AUTOSAR XML (schema 4-0-3)
package /ComponentTypes
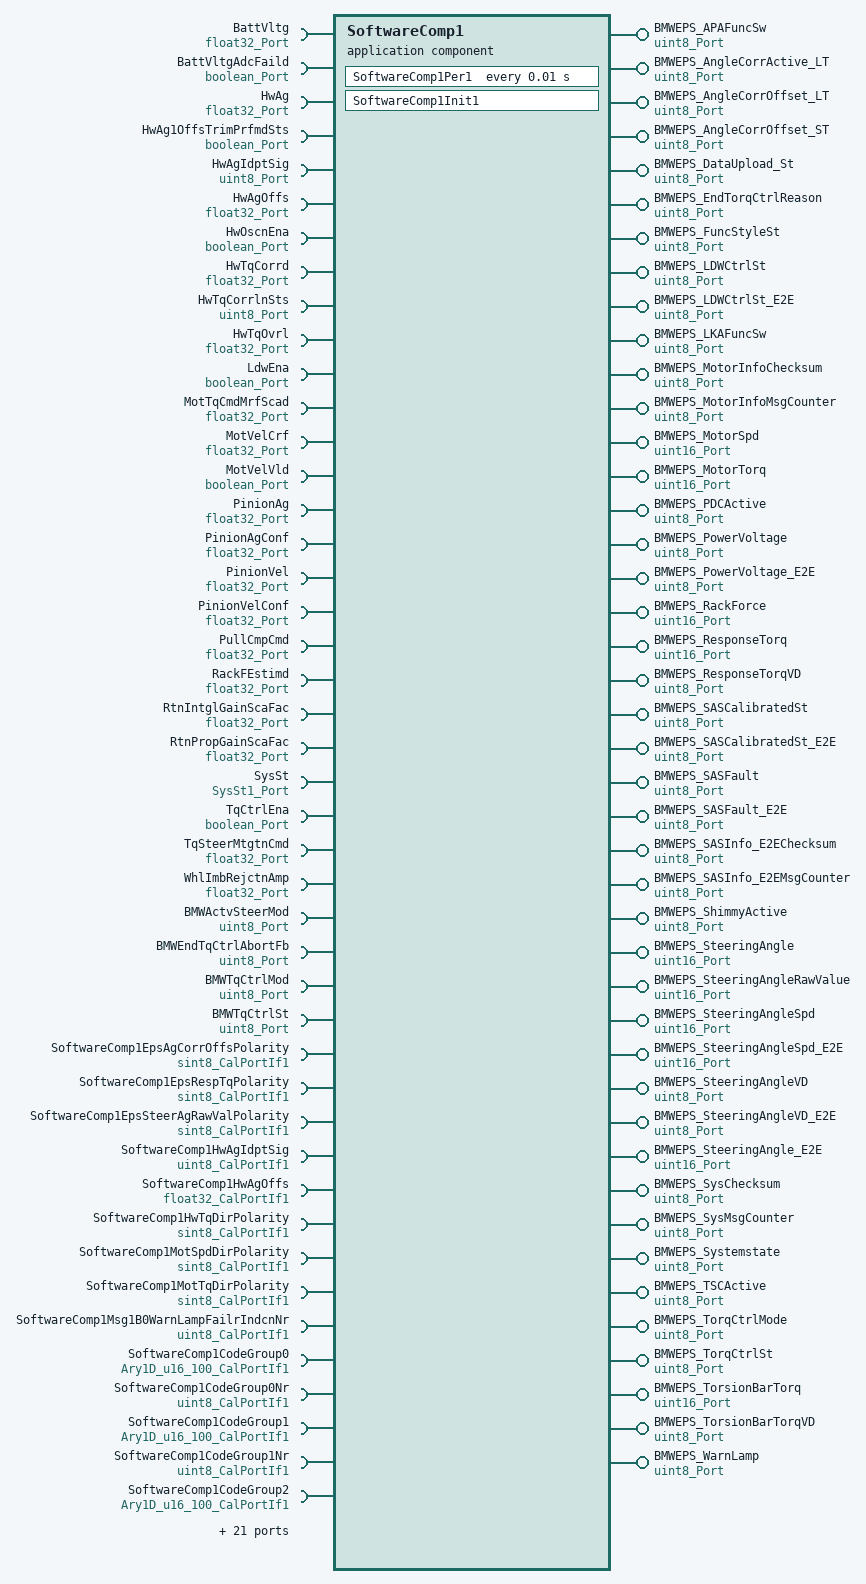
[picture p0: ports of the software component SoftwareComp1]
  application sw component type SoftwareComp1
    30 x require port:
      BattVltg: nonqueued-receiver-com-spec{data-element=Val, init-value=0}, required-interface=float32_Port
      BattVltgAdcFaild: nonqueued-receiver-com-spec{data-element=Logical, init-value=0}, required-interface=boolean_Port
      HwAg: nonqueued-receiver-com-spec{data-element=Val, init-value=0}, required-interface=float32_Port
      HwAg1OffsTrimPrfmdSts: nonqueued-receiver-com-spec{data-element=Logical, init-value=0}, required-interface=boolean_Port
      HwAgIdptSig: nonqueued-receiver-com-spec{data-element=Val, init-value=2}, required-interface=uint8_Port
      HwAgOffs: nonqueued-receiver-com-spec{data-element=Val, init-value=0}, required-interface=float32_Port
      HwOscnEna: nonqueued-receiver-com-spec{data-element=Logical, init-value=0}, required-interface=boolean_Port
      HwTqCorrd: nonqueued-receiver-com-spec{data-element=Val, init-value=0}, required-interface=float32_Port
      HwTqCorrlnSts: nonqueued-receiver-com-spec{data-element=Val, init-value=3}, required-interface=uint8_Port
      HwTqOvrl: nonqueued-receiver-com-spec{data-element=Val, init-value=0}, required-interface=float32_Port
      LdwEna: nonqueued-receiver-com-spec{data-element=Logical, init-value=0}, required-interface=boolean_Port
      MotTqCmdMrfScad: nonqueued-receiver-com-spec{data-element=Val, init-value=0}, required-interface=float32_Port
      MotVelCrf: nonqueued-receiver-com-spec{data-element=Val, init-value=0}, required-interface=float32_Port
      MotVelVld: nonqueued-receiver-com-spec{data-element=Logical, init-value=0}, required-interface=boolean_Port
      PinionAg: nonqueued-receiver-com-spec{data-element=Val, init-value=0}, required-interface=float32_Port
      PinionAgConf: nonqueued-receiver-com-spec{data-element=Val, init-value=0}, required-interface=float32_Port
      PinionVel: nonqueued-receiver-com-spec{data-element=Val, init-value=0}, required-interface=float32_Port
      PinionVelConf: nonqueued-receiver-com-spec{data-element=Val, init-value=0}, required-interface=float32_Port
      PullCmpCmd: nonqueued-receiver-com-spec{data-element=Val, init-value=0}, required-interface=float32_Port
      RackFEstimd: nonqueued-receiver-com-spec{data-element=Val, init-value=0}, required-interface=float32_Port
      RtnIntglGainScaFac: nonqueued-receiver-com-spec{data-element=Val, init-value=0}, required-interface=float32_Port
      RtnPropGainScaFac: nonqueued-receiver-com-spec{data-element=Val, init-value=0}, required-interface=float32_Port
      SysSt: nonqueued-receiver-com-spec{data-element=Val, init-value=3}, required-interface=SysSt1_Port
      TqCtrlEna: nonqueued-receiver-com-spec{data-element=Logical, init-value=0}, required-interface=boolean_Port
      TqSteerMtgtnCmd: nonqueued-receiver-com-spec{data-element=Val, init-value=0}, required-interface=float32_Port
      WhlImbRejctnAmp: nonqueued-receiver-com-spec{data-element=Val, init-value=0}, required-interface=float32_Port
      BMWActvSteerMod: nonqueued-receiver-com-spec{data-element=Val, init-value=0}, required-interface=uint8_Port
      BMWEndTqCtrlAbortFb: nonqueued-receiver-com-spec{data-element=Val, init-value=0}, required-interface=uint8_Port
      BMWTqCtrlMod: nonqueued-receiver-com-spec{data-element=Val, init-value=0}, required-interface=uint8_Port
      BMWTqCtrlSt: nonqueued-receiver-com-spec{data-element=Val, init-value=0}, required-interface=uint8_Port
    43 x provide port:
      BMWEPS_APAFuncSw: nonqueued-sender-com-spec{data-element=Val, init-value=0}, provided-interface=uint8_Port
      BMWEPS_AngleCorrActive_LT: nonqueued-sender-com-spec{data-element=Val, init-value=0}, provided-interface=uint8_Port
      BMWEPS_AngleCorrOffset_LT: nonqueued-sender-com-spec{data-element=Val, init-value=70}, provided-interface=uint8_Port
      BMWEPS_AngleCorrOffset_ST: nonqueued-sender-com-spec{data-element=Val, init-value=70}, provided-interface=uint8_Port
      BMWEPS_DataUpload_St: nonqueued-sender-com-spec{data-element=Val, init-value=0}, provided-interface=uint8_Port
      BMWEPS_EndTorqCtrlReason: nonqueued-sender-com-spec{data-element=Val, init-value=0}, provided-interface=uint8_Port
      BMWEPS_FuncStyleSt: nonqueued-sender-com-spec{data-element=Val, init-value=0}, provided-interface=uint8_Port
      BMWEPS_LDWCtrlSt: nonqueued-sender-com-spec{data-element=Val, init-value=0}, provided-interface=uint8_Port
      BMWEPS_LDWCtrlSt_E2E: nonqueued-sender-com-spec{data-element=Val, init-value=0}, provided-interface=uint8_Port
      BMWEPS_LKAFuncSw: nonqueued-sender-com-spec{data-element=Val, init-value=0}, provided-interface=uint8_Port
      BMWEPS_MotorInfoChecksum: nonqueued-sender-com-spec{data-element=Val, init-value=0}, provided-interface=uint8_Port
      BMWEPS_MotorInfoMsgCounter: nonqueued-sender-com-spec{data-element=Val, init-value=0}, provided-interface=uint8_Port
      BMWEPS_MotorSpd: nonqueued-sender-com-spec{data-element=Val, init-value=13000}, provided-interface=uint16_Port
      BMWEPS_MotorTorq: nonqueued-sender-com-spec{data-element=Val, init-value=75}, provided-interface=uint16_Port
      BMWEPS_PDCActive: nonqueued-sender-com-spec{data-element=Val, init-value=0}, provided-interface=uint8_Port
      BMWEPS_PowerVoltage: nonqueued-sender-com-spec{data-element=Val, init-value=0}, provided-interface=uint8_Port
      BMWEPS_PowerVoltage_E2E: nonqueued-sender-com-spec{data-element=Val, init-value=0}, provided-interface=uint8_Port
      BMWEPS_RackForce: nonqueued-sender-com-spec{data-element=Val, init-value=20000}, provided-interface=uint16_Port
      BMWEPS_ResponseTorq: nonqueued-sender-com-spec{data-element=Val, init-value=1024}, provided-interface=uint16_Port
      BMWEPS_ResponseTorqVD: nonqueued-sender-com-spec{data-element=Val, init-value=0}, provided-interface=uint8_Port
      BMWEPS_SASCalibratedSt: nonqueued-sender-com-spec{data-element=Val, init-value=0}, provided-interface=uint8_Port
      BMWEPS_SASCalibratedSt_E2E: nonqueued-sender-com-spec{data-element=Val, init-value=0}, provided-interface=uint8_Port
      BMWEPS_SASFault: nonqueued-sender-com-spec{data-element=Val, init-value=0}, provided-interface=uint8_Port
      BMWEPS_SASFault_E2E: nonqueued-sender-com-spec{data-element=Val, init-value=0}, provided-interface=uint8_Port
      BMWEPS_SASInfo_E2EChecksum: nonqueued-sender-com-spec{data-element=Val, init-value=0}, provided-interface=uint8_Port
      BMWEPS_SASInfo_E2EMsgCounter: nonqueued-sender-com-spec{data-element=Val, init-value=0}, provided-interface=uint8_Port
      BMWEPS_ShimmyActive: nonqueued-sender-com-spec{data-element=Val, init-value=0}, provided-interface=uint8_Port
      BMWEPS_SteeringAngle: nonqueued-sender-com-spec{data-element=Val, init-value=7800}, provided-interface=uint16_Port
      BMWEPS_SteeringAngleRawValue: nonqueued-sender-com-spec{data-element=Val, init-value=7800}, provided-interface=uint16_Port
      BMWEPS_SteeringAngleSpd: nonqueued-sender-com-spec{data-element=Val, init-value=1016}, provided-interface=uint16_Port
      BMWEPS_SteeringAngleSpd_E2E: nonqueued-sender-com-spec{data-element=Val, init-value=1016}, provided-interface=uint16_Port
      BMWEPS_SteeringAngleVD: nonqueued-sender-com-spec{data-element=Val, init-value=0}, provided-interface=uint8_Port
      BMWEPS_SteeringAngleVD_E2E: nonqueued-sender-com-spec{data-element=Val, init-value=0}, provided-interface=uint8_Port
      BMWEPS_SteeringAngle_E2E: nonqueued-sender-com-spec{data-element=Val, init-value=7800}, provided-interface=uint16_Port
      BMWEPS_SysChecksum: nonqueued-sender-com-spec{data-element=Val, init-value=0}, provided-interface=uint8_Port
      BMWEPS_SysMsgCounter: nonqueued-sender-com-spec{data-element=Val, init-value=0}, provided-interface=uint8_Port
      BMWEPS_Systemstate: nonqueued-sender-com-spec{data-element=Val, init-value=0}, provided-interface=uint8_Port
      BMWEPS_TSCActive: nonqueued-sender-com-spec{data-element=Val, init-value=0}, provided-interface=uint8_Port
      BMWEPS_TorqCtrlMode: nonqueued-sender-com-spec{data-element=Val, init-value=0}, provided-interface=uint8_Port
      BMWEPS_TorqCtrlSt: nonqueued-sender-com-spec{data-element=Val, init-value=0}, provided-interface=uint8_Port
      BMWEPS_TorsionBarTorq: nonqueued-sender-com-spec{data-element=Val, init-value=1024}, provided-interface=uint16_Port
      BMWEPS_TorsionBarTorqVD: nonqueued-sender-com-spec{data-element=Val, init-value=0}, provided-interface=uint8_Port
      BMWEPS_WarnLamp: nonqueued-sender-com-spec{data-element=Val, init-value=0}, provided-interface=uint8_Port
    35 x require port:
      SoftwareComp1EpsAgCorrOffsPolarity: parameter-require-com-spec{init-value=-1, parameter=Val}, required-interface=sint8_CalPortIf1
      SoftwareComp1EpsRespTqPolarity: parameter-require-com-spec{init-value=-1, parameter=Val}, required-interface=sint8_CalPortIf1
      SoftwareComp1EpsSteerAgRawValPolarity: parameter-require-com-spec{init-value=-1, parameter=Val}, required-interface=sint8_CalPortIf1
      SoftwareComp1HwAgIdptSig: parameter-require-com-spec{init-value=1, parameter=Val}, required-interface=uint8_CalPortIf1
      SoftwareComp1HwAgOffs: parameter-require-com-spec{init-value=0, parameter=Val}, required-interface=float32_CalPortIf1
      SoftwareComp1HwTqDirPolarity: parameter-require-com-spec{init-value=-1, parameter=Val}, required-interface=sint8_CalPortIf1
      SoftwareComp1MotSpdDirPolarity: parameter-require-com-spec{init-value=-1, parameter=Val}, required-interface=sint8_CalPortIf1
      SoftwareComp1MotTqDirPolarity: parameter-require-com-spec{init-value=-1, parameter=Val}, required-interface=sint8_CalPortIf1
      SoftwareComp1Msg1B0WarnLampFailrIndcnNr: parameter-require-com-spec{init-value=1, parameter=Val}, required-interface=uint8_CalPortIf1
      SoftwareComp1CodeGroup0: parameter-require-com-spec{init-value=100 x 1, parameter=Ary1D}, required-interface=Ary1D_u16_100_CalPortIf1
      SoftwareComp1CodeGroup0Nr: parameter-require-com-spec{init-value=100, parameter=Val}, required-interface=uint8_CalPortIf1
      SoftwareComp1CodeGroup1: parameter-require-com-spec{init-value=100 x 1, parameter=Ary1D}, required-interface=Ary1D_u16_100_CalPortIf1
      SoftwareComp1CodeGroup1Nr: parameter-require-com-spec{init-value=100, parameter=Val}, required-interface=uint8_CalPortIf1
      SoftwareComp1CodeGroup2: parameter-require-com-spec{init-value=100 x 1, parameter=Ary1D}, required-interface=Ary1D_u16_100_CalPortIf1
      SoftwareComp1CodeGroup2Nr: parameter-require-com-spec{init-value=100, parameter=Val}, required-interface=uint8_CalPortIf1
      SoftwareComp1CodeGroup3: parameter-require-com-spec{init-value=[1, 1, 1, 1, 1, 1, 1, 1, 1, 1, 1, 1, 1, 1, 1, 1, 1, 1, 1, 1, 1, 1, 1, 1, 1, 1, 1, 1, 1, 1, 1, 1, 1, 1, 1, 1, 1, 1, 1, 1, 1, 1, 1, 1, 1, 1, 1, 1, 0, 0, 0, 1, 1, 1, 1, 1, 1, 1, 1, 1, 1, 1, 1, 1, 1, 1, 1, 1, 1, 1, 1, 1, 1, 1, 1, 1, 1, 1, 1, 1, 1, 1, 1, 1, 1, 1, 1, 1, 1, 1, 1, 1, 1, 1, 1, 1, 1, 1, 1, 1], parameter=Ary1D}, required-interface=Ary1D_u16_100_CalPortIf1
      SoftwareComp1CodeGroup3Nr: parameter-require-com-spec{init-value=100, parameter=Val}, required-interface=uint8_CalPortIf1
      SoftwareComp1CodeGroup4: parameter-require-com-spec{init-value=100 x 1, parameter=Ary1D}, required-interface=Ary1D_u16_100_CalPortIf1
      SoftwareComp1CodeGroup4Nr: parameter-require-com-spec{init-value=100, parameter=Val}, required-interface=uint8_CalPortIf1
      SoftwareComp1CodeGroup5: parameter-require-com-spec{init-value=100 x 0, parameter=Ary1D}, required-interface=Ary1D_u16_100_CalPortIf1
      SoftwareComp1CodeGroup5Nr: parameter-require-com-spec{init-value=100, parameter=Val}, required-interface=uint8_CalPortIf1
      SoftwareComp1PinionAgConfDftVal: parameter-require-com-spec{init-value=1, parameter=Val}, required-interface=float32_CalPortIf1
      SoftwareComp1PinionAgDirPolarity: parameter-require-com-spec{init-value=-1, parameter=Val}, required-interface=sint8_CalPortIf1
      SoftwareComp1PinionVelConfVal: parameter-require-com-spec{init-value=1, parameter=Val}, required-interface=float32_CalPortIf1
      SoftwareComp1PinionVelDirPolarity: parameter-require-com-spec{init-value=-1, parameter=Val}, required-interface=sint8_CalPortIf1
      SoftwareComp1PullCmpCmdVal: parameter-require-com-spec{init-value=0, parameter=Val}, required-interface=float32_CalPortIf1
      SoftwareComp1RackFDirPolarity: parameter-require-com-spec{init-value=-1, parameter=Val}, required-interface=sint8_CalPortIf1
      SoftwareComp1RtnIntglGainScaFac: parameter-require-com-spec{init-value=0, parameter=Val}, required-interface=float32_CalPortIf1
      SoftwareComp1RtnPropGainScaFac: parameter-require-com-spec{init-value=0, parameter=Val}, required-interface=float32_CalPortIf1
      SoftwareComp1TqSteerMtgtnCmdVal: parameter-require-com-spec{init-value=0, parameter=Val}, required-interface=float32_CalPortIf1
      SoftwareComp1WhlImbRejctnAmpVal: parameter-require-com-spec{init-value=0, parameter=Val}, required-interface=float32_CalPortIf1
      SoftwareComp1Msg113CfgPtrCal: parameter-require-com-spec{init-value=fields=[CntrOffs:88, CrcOffs:96, DataID:785, DataIDNiblOffs:0, DataIDMod:1, DataLen:20, 2, MaxNoNewOrRepData:14, 1], parameter=Rec}, required-interface=P01CfgRec2_CalPortIf1
      SoftwareComp1Msg1B0CfgPtrCal: parameter-require-com-spec{init-value=fields=[CntrOffs:120, CrcOffs:96, DataID:177, DataIDNiblOffs:0, DataIDMod:1, DataLen:20, 2, MaxNoNewOrRepData:14, 1], parameter=Rec}, required-interface=P01CfgRec2_CalPortIf1
      SoftwareComp1Msg1B1CfgPtrCal: parameter-require-com-spec{init-value=fields=[CntrOffs:32, CrcOffs:40, DataID:433, DataIDNiblOffs:0, DataIDMod:1, DataLen:20, 2, MaxNoNewOrRepData:14, 1], parameter=Rec}, required-interface=P01CfgRec2_CalPortIf1
      GetCodeQlfrSts: client-com-spec=Oper, required-interface=GetCodeQlfrSts_Port
    behavior SoftwareComp1_InternalBehavior
      ar-typed-per-instance-memorys:
        13 x data, all with sw-calibration-access=READ-ONLY:
          Msg113InfoChks: type=uint8
          Msg113InfoCntr: type=uint8
          Msg113P01StPtr: type=P01ProtStRec1
          Msg115InfoCntr: type=uint8
          Msg1B0InfoChks: type=uint8
          Msg1B0InfoCntr: type=uint8
          Msg1B0P01StPtr: type=P01ProtStRec1
          Msg1B1InfoChks: type=uint8
          Msg1B1InfoCntr: type=uint8
          Msg1B1P01StPtr: type=P01ProtStRec1
          CodeFirstIdx: type=uint8
          CodeGroupForFltVal: type=boolean
          SoftwareComp1MsgTxCntr: type=uint8
      init event SoftwareComp1_InitEvent: start-on-event=SoftwareComp1Init1
      timing event TMT_SoftwareComp1Per1: start-on-event=SoftwareComp1Per1, period=0.01
      runnable SoftwareComp1Init1
      runnable SoftwareComp1Per1
        data-receive-point-by-arguments:
          30 x access:
            REC_BattVltg_Val: accessed-variable=BattVltg.Val
            REC_BattVltgAdcFaild_Logical: accessed-variable=BattVltgAdcFaild.Logical
            REC_HwAg_Val: accessed-variable=HwAg.Val
            REC_HwAg1OffsTrimPrfmdSts_Logical: accessed-variable=HwAg1OffsTrimPrfmdSts.Logical
            REC_HwAgIdptSig_Val: accessed-variable=HwAgIdptSig.Val
            REC_HwAgOffs_Val: accessed-variable=HwAgOffs.Val
            REC_HwOscnEna_Logical: accessed-variable=HwOscnEna.Logical
            REC_HwTqCorrd_Val: accessed-variable=HwTqCorrd.Val
            REC_HwTqCorrlnSts_Val: accessed-variable=HwTqCorrlnSts.Val
            REC_HwTqOvrl_Val: accessed-variable=HwTqOvrl.Val
            REC_LdwEna_Logical: accessed-variable=LdwEna.Logical
            REC_MotTqCmdMrfScad_Val: accessed-variable=MotTqCmdMrfScad.Val
            REC_MotVelCrf_Val: accessed-variable=MotVelCrf.Val
            REC_MotVelVld_Logical: accessed-variable=MotVelVld.Logical
            REC_PinionAg_Val: accessed-variable=PinionAg.Val
            REC_PinionAgConf_Val: accessed-variable=PinionAgConf.Val
            REC_PinionVel_Val: accessed-variable=PinionVel.Val
            REC_PinionVelConf_Val: accessed-variable=PinionVelConf.Val
            REC_PullCmpCmd_Val: accessed-variable=PullCmpCmd.Val
            REC_RackFEstimd_Val: accessed-variable=RackFEstimd.Val
            REC_RtnIntglGainScaFac_Val: accessed-variable=RtnIntglGainScaFac.Val
            REC_RtnPropGainScaFac_Val: accessed-variable=RtnPropGainScaFac.Val
            REC_SysSt_Val: accessed-variable=SysSt.Val
            REC_TqCtrlEna_Logical: accessed-variable=TqCtrlEna.Logical
            REC_TqSteerMtgtnCmd_Val: accessed-variable=TqSteerMtgtnCmd.Val
            REC_WhlImbRejctnAmp_Val: accessed-variable=WhlImbRejctnAmp.Val
            REC_BMWActvSteerMod_Val: accessed-variable=BMWActvSteerMod.Val
            REC_BMWEndTqCtrlAbortFb_Val: accessed-variable=BMWEndTqCtrlAbortFb.Val
            REC_BMWTqCtrlMod_Val: accessed-variable=BMWTqCtrlMod.Val
            REC_BMWTqCtrlSt_Val: accessed-variable=BMWTqCtrlSt.Val
        data-send-points:
          43 x access:
            SEND_BMWEPS_APAFuncSw_Val: accessed-variable=BMWEPS_APAFuncSw.Val
            SEND_BMWEPS_AngleCorrActive_LT_Val: accessed-variable=BMWEPS_AngleCorrActive_LT.Val
            SEND_BMWEPS_AngleCorrOffset_LT_Val: accessed-variable=BMWEPS_AngleCorrOffset_LT.Val
            SEND_BMWEPS_AngleCorreOffset_ST_Val: accessed-variable=BMWEPS_AngleCorrOffset_ST.Val
            SEND_BMWEPS_DataUpload_St_Val: accessed-variable=BMWEPS_DataUpload_St.Val
            SEND_BMWEPS_EndTorqCtrlReason_Val: accessed-variable=BMWEPS_EndTorqCtrlReason.Val
            SEND_BMWEPS_FuncStyleSt_Val: accessed-variable=BMWEPS_FuncStyleSt.Val
            SEND_BMWEPS_LDWCtrlSt_Val: accessed-variable=BMWEPS_LDWCtrlSt.Val
            SEND_BMWEPS_LDWCtrlSt_E2E_Val: accessed-variable=BMWEPS_LDWCtrlSt_E2E.Val
            SEND_BMWEPS_LKAFuncSw_Val: accessed-variable=BMWEPS_LKAFuncSw.Val
            SEND_BMWEPS_MotorInfoChecksum_Val: accessed-variable=BMWEPS_MotorInfoChecksum.Val
            SEND_BMWEPS_MotorInfoMsgCounter_Val: accessed-variable=BMWEPS_MotorInfoMsgCounter.Val
            SEND_BMWEPS_MotorTorq_Val: accessed-variable=BMWEPS_MotorTorq.Val
            SEND_BMWEPS_PDCActive_Val: accessed-variable=BMWEPS_PDCActive.Val
            SEND_BMWEPS_PowerVoltage_Val: accessed-variable=BMWEPS_PowerVoltage.Val
            SEND_BMWEPS_PowerVoltage_E2E_Val: accessed-variable=BMWEPS_PowerVoltage_E2E.Val
            SEND_BMWEPS_RackForce_Val: accessed-variable=BMWEPS_RackForce.Val
            SEND_BMWEPS_ResponseTorq_Val: accessed-variable=BMWEPS_ResponseTorq.Val
            SEND_BMWEPS_ResponseTorqVD_Val: accessed-variable=BMWEPS_ResponseTorqVD.Val
            SEND_BMWEPS_SASCalibratedSt_Val: accessed-variable=BMWEPS_SASCalibratedSt.Val
            SEND_BMWEPS_SASCalibratedSt_E2E_Val: accessed-variable=BMWEPS_SASCalibratedSt_E2E.Val
            SEND_BMWEPS_SASFault_Val: accessed-variable=BMWEPS_SASFault.Val
            SEND_BMWEPS_SASFault_E2E_Val: accessed-variable=BMWEPS_SASFault_E2E.Val
            SEND_BMWEPS_SASInfo_E2EChecksum_Val: accessed-variable=BMWEPS_SASInfo_E2EChecksum.Val
            SEND_BMWEPS_SASInfo_E2EMsgCounter_Val: accessed-variable=BMWEPS_SASInfo_E2EMsgCounter.Val
            SEND_BMWEPS_ShimmyActive_Val: accessed-variable=BMWEPS_ShimmyActive.Val
            SEND_BMWEPS_SteeringAngle_Val: accessed-variable=BMWEPS_SteeringAngle.Val
            SEND_BMWEPS_SteeringAngleRawValue_Val: accessed-variable=BMWEPS_SteeringAngleRawValue.Val
            SEND_BMWEPS_SteeringAngleSpd_Val: accessed-variable=BMWEPS_SteeringAngleSpd.Val
            SEND_BMWEPS_SteeringAngleSpd_E2E_Val: accessed-variable=BMWEPS_SteeringAngleSpd_E2E.Val
            SEND_BMWEPS_SteeringAngleVD_Val: accessed-variable=BMWEPS_SteeringAngleVD.Val
            SEND_BMWEPS_SteeringAngleVD_E2E_Val: accessed-variable=BMWEPS_SteeringAngleVD_E2E.Val
            SEND_BMWEPS_SteeringAngle_E2E_Val: accessed-variable=BMWEPS_SteeringAngle_E2E.Val
            SEND_BMWEPS_SysChecksum_Val: accessed-variable=BMWEPS_SysChecksum.Val
            SEND_BMWEPS_SysMsgCounter_Val: accessed-variable=BMWEPS_SysMsgCounter.Val
            SEND_BMWEPS_Systemstate_Val: accessed-variable=BMWEPS_Systemstate.Val
            SEND_BMWEPS_TSCActive_Val: accessed-variable=BMWEPS_TSCActive.Val
            SEND_BMWEPS_TorqCtrlMode_Val: accessed-variable=BMWEPS_TorqCtrlMode.Val
            SEND_BMWEPS_TorqCtrlSt_Val: accessed-variable=BMWEPS_TorqCtrlSt.Val
            SEND_BMWEPS_TorsionBarTorq_Val: accessed-variable=BMWEPS_TorsionBarTorq.Val
            SEND_BMWEPS_TorsionBarTorqVD_Val: accessed-variable=BMWEPS_TorsionBarTorqVD.Val
            SEND_BMWEPS_WarnLamp_Val: accessed-variable=BMWEPS_WarnLamp.Val
            SEND_BMWEPS_MotorSpd_Val: accessed-variable=BMWEPS_MotorSpd.Val
        sync call SC_GetCodeQlfrSts_Oper: operation=GetCodeQlfrSts.Oper
  swc implementation SoftwareComp1_Implementation: behavior=SoftwareComp1_InternalBehavior
